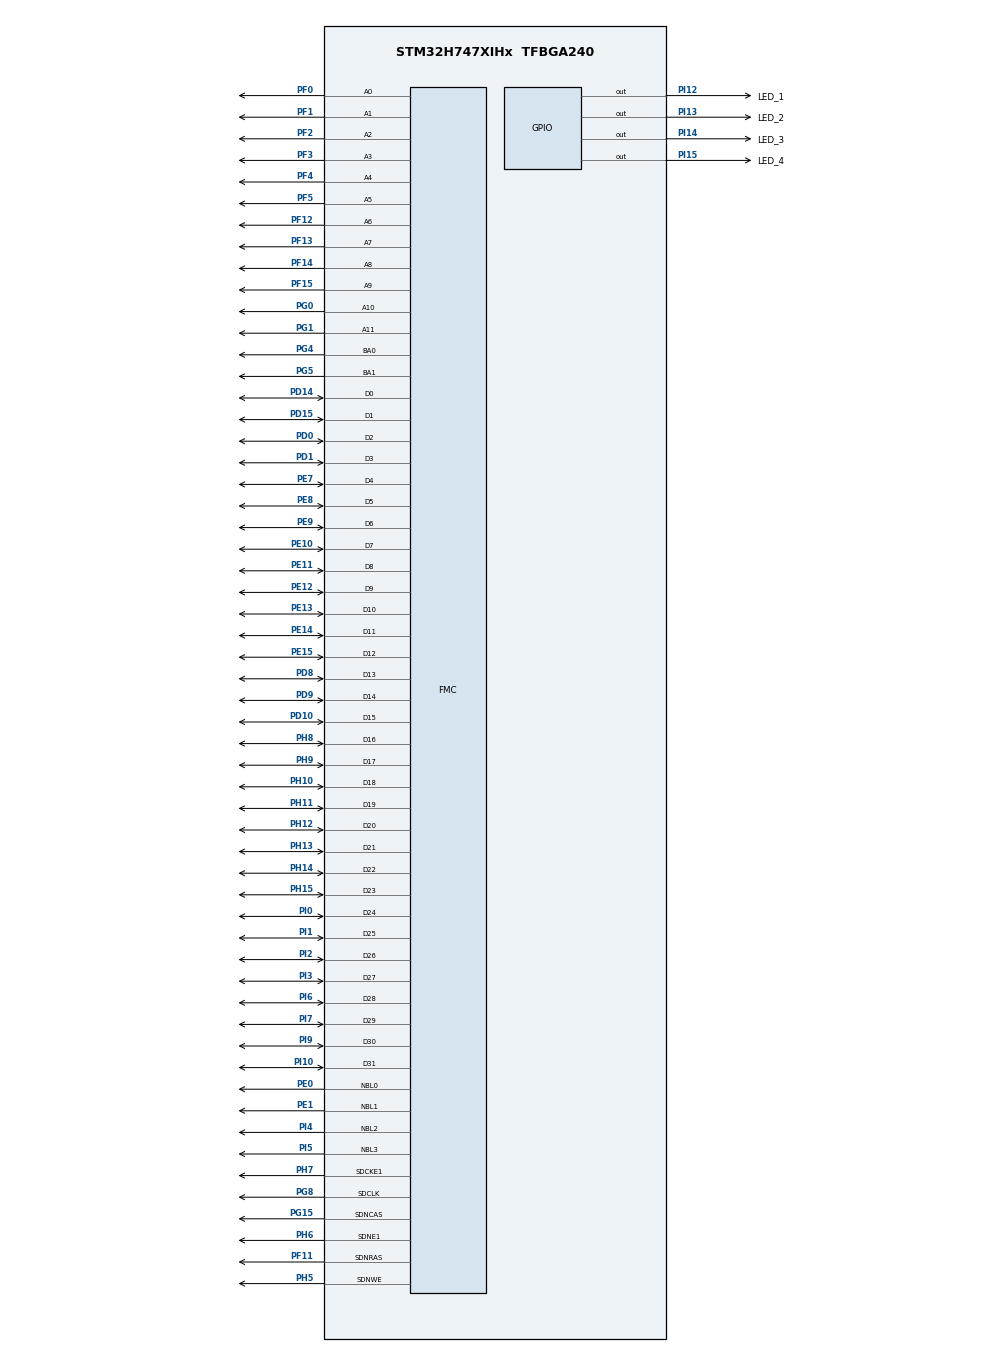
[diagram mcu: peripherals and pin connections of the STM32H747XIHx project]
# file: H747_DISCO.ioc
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CORTEX_M7.CPU_DCache=Enabled
CORTEX_M7.CPU_ICache=Enabled
CortexM4.IPs=BDMA,DMA,FATFS_M4\:I,FREERTOS_M4\:I,IWDG2\:I,MDMA,NVIC2\:I,RCC,USB_DEVICE_M4\:I,USB_HOST_M4\:I,WWDG2\:I,DEBUG,PDM2PCM_M4\:I,PWR,RESMGR_UTILITY,SYS_M4\:I,CORTEX_M4\:I,OPENAMP_M4\:I,VREFBUF,GPIO
CortexM4.Pins=PI14,PI15
CortexM7.IPs=BDMA\:I,DMA\:I,FATFS_M7\:I,FREERTOS_M7\:I,IWDG1\:I,MDMA\:I,NVIC1\:I,RCC\:I,USB_DEVICE_M7\:I,USB_HOST_M7\:I,WWDG1\:I,CORTEX_M7\:I,DEBUG\:I,PDM2PCM_M7\:I,PWR\:I,RESMGR_UTILITY\:I,SYS\:I,OPENAMP_M7\:I,VREFBUF\:I,GPIO\:I,FMC\:I
CortexM7.Pins=PI12,PI13
FMC.ColumnBitsNumber1=FMC_SDRAM_COLUMN_BITS_NUM_9
FMC.ReadPipeDelay1=FMC_SDRAM_RPIPE_DELAY_2
FMC.SDClockPeriod1=FMC_SDRAM_CLOCK_PERIOD_2
Mcu.Family=STM32H7
Mcu.Name=STM32H747XIHx
Mcu.Package=TFBGA240
NVIC1.PriorityGroup=NVIC_PRIORITYGROUP_4
NVIC2.PriorityGroup=NVIC_PRIORITYGROUP_4
PD0.PinAttribute=CortexM7
PD0.Signal=FMC_D2_DA2
PD1.PinAttribute=CortexM7
PD1.Signal=FMC_D3_DA3
PD10.PinAttribute=CortexM7
PD10.Signal=FMC_D15_DA15
PD14.PinAttribute=CortexM7
PD14.Signal=FMC_D0_DA0
PD15.PinAttribute=CortexM7
PD15.Signal=FMC_D1_DA1
PD8.PinAttribute=CortexM7
PD8.Signal=FMC_D13_DA13
PD9.PinAttribute=CortexM7
PD9.Signal=FMC_D14_DA14
PE0.PinAttribute=CortexM7
PE0.Signal=FMC_NBL0
PE1.PinAttribute=CortexM7
PE1.Signal=FMC_NBL1
PE10.PinAttribute=CortexM7
PE10.Signal=FMC_D7_DA7
PE11.PinAttribute=CortexM7
PE11.Signal=FMC_D8_DA8
PE12.PinAttribute=CortexM7
PE12.Signal=FMC_D9_DA9
PE13.PinAttribute=CortexM7
PE13.Signal=FMC_D10_DA10
PE14.PinAttribute=CortexM7
PE14.Signal=FMC_D11_DA11
PE15.PinAttribute=CortexM7
PE15.Signal=FMC_D12_DA12
PE7.PinAttribute=CortexM7
PE7.Signal=FMC_D4_DA4
PE8.PinAttribute=CortexM7
PE8.Signal=FMC_D5_DA5
PE9.PinAttribute=CortexM7
PE9.Signal=FMC_D6_DA6
PF0.PinAttribute=CortexM7
PF0.Signal=FMC_A0
PF1.PinAttribute=CortexM7
PF1.Signal=FMC_A1
PF11.PinAttribute=CortexM7
PF11.Signal=FMC_SDNRAS
PF12.PinAttribute=CortexM7
PF12.Signal=FMC_A6
PF13.PinAttribute=CortexM7
PF13.Signal=FMC_A7
PF14.PinAttribute=CortexM7
PF14.Signal=FMC_A8
PF15.PinAttribute=CortexM7
PF15.Signal=FMC_A9
PF2.PinAttribute=CortexM7
PF2.Signal=FMC_A2
PF3.PinAttribute=CortexM7
PF3.Signal=FMC_A3
PF4.PinAttribute=CortexM7
PF4.Signal=FMC_A4
PF5.PinAttribute=CortexM7
PF5.Signal=FMC_A5
PG0.PinAttribute=CortexM7
PG0.Signal=FMC_A10
PG1.PinAttribute=CortexM7
PG1.Signal=FMC_A11
PG15.PinAttribute=CortexM7
PG15.Signal=FMC_SDNCAS
PG4.PinAttribute=CortexM7
PG4.Signal=FMC_A14_BA0
PG5.PinAttribute=CortexM7
PG5.Signal=FMC_A15_BA1
PG8.PinAttribute=CortexM7
PG8.Signal=FMC_SDCLK
PH10.PinAttribute=CortexM7
PH10.Signal=FMC_D18
PH11.PinAttribute=CortexM7
PH11.Signal=FMC_D19
PH12.PinAttribute=CortexM7
PH12.Signal=FMC_D20
PH13.PinAttribute=CortexM7
PH13.Signal=FMC_D21
PH14.PinAttribute=CortexM7
PH14.Signal=FMC_D22
PH15.PinAttribute=CortexM7
PH15.Signal=FMC_D23
PH5.PinAttribute=CortexM7
PH5.Signal=FMC_SDNWE
PH6.Mode=SdramChipSelect2_1
PH6.PinAttribute=CortexM7
PH6.Signal=FMC_SDNE1
PH7.Mode=SdramChipSelect2_1
PH7.PinAttribute=CortexM7
PH7.Signal=FMC_SDCKE1
PH8.PinAttribute=CortexM7
PH8.Signal=FMC_D16
PH9.PinAttribute=CortexM7
PH9.Signal=FMC_D17
PI0.PinAttribute=CortexM7
PI0.Signal=FMC_D24
PI1.PinAttribute=CortexM7
PI1.Signal=FMC_D25
PI10.PinAttribute=CortexM7
PI10.Signal=FMC_D31
PI12.GPIO_Label=LED_1
PI12.PinAttribute=CortexM7
PI12.Signal=GPIO_Output
PI13.GPIO_Label=LED_2
PI13.PinAttribute=CortexM7
PI13.Signal=GPIO_Output
PI14.GPIO_Label=LED_3
PI14.PinAttribute=CortexM4
PI14.Signal=GPIO_Output
PI15.GPIO_Label=LED_4
PI15.PinAttribute=CortexM4
PI15.Signal=GPIO_Output
PI2.PinAttribute=CortexM7
PI2.Signal=FMC_D26
PI3.PinAttribute=CortexM7
PI3.Signal=FMC_D27
PI4.PinAttribute=CortexM7
PI4.Signal=FMC_NBL2
PI5.PinAttribute=CortexM7
PI5.Signal=FMC_NBL3
PI6.PinAttribute=CortexM7
PI6.Signal=FMC_D28
PI7.PinAttribute=CortexM7
PI7.Signal=FMC_D29
PI9.PinAttribute=CortexM7
PI9.Signal=FMC_D30
ProjectManager.HeapSize=M4-0x200,M7-0x200
ProjectManager.StackSize=M4-0x400,M7-0x400
ProjectManager.TargetToolchain=STM32CubeIDE
RCC.ADCFreq_Value=192000000
RCC.APB1Freq_Value=100000000
RCC.APB2Freq_Value=100000000
RCC.APB3Freq_Value=100000000
RCC.APB4Freq_Value=100000000
RCC.CortexFreq_Value=400000000
RCC.D1PPRE=RCC_APB3_DIV2
RCC.D2PPRE1=RCC_APB1_DIV2
RCC.D2PPRE2=RCC_APB2_DIV2
RCC.D3PPRE=RCC_APB4_DIV2
RCC.DIVM1=4
RCC.DIVM2=2
RCC.DIVN1=50
RCC.DIVN2=12
RCC.DIVQ1=5
RCC.HCLKFreq_Value=200000000
RCC.HPRE=RCC_HCLK_DIV2
RCC.PLL2FRACN=0
RCC.PLL3FRACN=0
RCC.PLLFRACN=0
RCC.PWR_Regulator_Voltage_Scale=PWR_REGULATOR_VOLTAGE_SCALE1
RCC.SYSCLKFreq_VALUE=400000000
RCC.SYSCLKSource=RCC_SYSCLKSOURCE_PLLCLK
RCC.SupplySource=PWR_DIRECT_SMPS_SUPPLY
RCC.USBFreq_Value=160000000
SH.FMC_A0.0=FMC_A0,12b-sda1
SH.FMC_A1.0=FMC_A1,12b-sda1
SH.FMC_A10.0=FMC_A10,12b-sda1
SH.FMC_A11.0=FMC_A11,12b-sda1
SH.FMC_A14_BA0.0=FMC_BA0,FourSdramBanks1
SH.FMC_A15_BA1.0=FMC_BA1,FourSdramBanks1
SH.FMC_A2.0=FMC_A2,12b-sda1
SH.FMC_A3.0=FMC_A3,12b-sda1
SH.FMC_A4.0=FMC_A4,12b-sda1
SH.FMC_A5.0=FMC_A5,12b-sda1
SH.FMC_A6.0=FMC_A6,12b-sda1
SH.FMC_A7.0=FMC_A7,12b-sda1
SH.FMC_A8.0=FMC_A8,12b-sda1
SH.FMC_A9.0=FMC_A9,12b-sda1
SH.FMC_D0_DA0.0=FMC_D0,sd-32b-d1
SH.FMC_D10_DA10.0=FMC_D10,sd-32b-d1
SH.FMC_D11_DA11.0=FMC_D11,sd-32b-d1
SH.FMC_D12_DA12.0=FMC_D12,sd-32b-d1
SH.FMC_D13_DA13.0=FMC_D13,sd-32b-d1
SH.FMC_D14_DA14.0=FMC_D14,sd-32b-d1
SH.FMC_D15_DA15.0=FMC_D15,sd-32b-d1
SH.FMC_D16.0=FMC_D16,sd-32b-d1
SH.FMC_D17.0=FMC_D17,sd-32b-d1
SH.FMC_D18.0=FMC_D18,sd-32b-d1
SH.FMC_D19.0=FMC_D19,sd-32b-d1
SH.FMC_D1_DA1.0=FMC_D1,sd-32b-d1
SH.FMC_D20.0=FMC_D20,sd-32b-d1
SH.FMC_D21.0=FMC_D21,sd-32b-d1
SH.FMC_D22.0=FMC_D22,sd-32b-d1
SH.FMC_D23.0=FMC_D23,sd-32b-d1
SH.FMC_D24.0=FMC_D24,sd-32b-d1
SH.FMC_D25.0=FMC_D25,sd-32b-d1
SH.FMC_D26.0=FMC_D26,sd-32b-d1
SH.FMC_D27.0=FMC_D27,sd-32b-d1
SH.FMC_D28.0=FMC_D28,sd-32b-d1
SH.FMC_D29.0=FMC_D29,sd-32b-d1
SH.FMC_D2_DA2.0=FMC_D2,sd-32b-d1
SH.FMC_D30.0=FMC_D30,sd-32b-d1
SH.FMC_D31.0=FMC_D31,sd-32b-d1
SH.FMC_D3_DA3.0=FMC_D3,sd-32b-d1
SH.FMC_D4_DA4.0=FMC_D4,sd-32b-d1
SH.FMC_D5_DA5.0=FMC_D5,sd-32b-d1
SH.FMC_D6_DA6.0=FMC_D6,sd-32b-d1
SH.FMC_D7_DA7.0=FMC_D7,sd-32b-d1
SH.FMC_D8_DA8.0=FMC_D8,sd-32b-d1
SH.FMC_D9_DA9.0=FMC_D9,sd-32b-d1
SH.FMC_NBL0.0=FMC_NBL0,Sd4ByteEnable1
SH.FMC_NBL1.0=FMC_NBL1,Sd4ByteEnable1
SH.FMC_NBL2.0=FMC_NBL2,Sd4ByteEnable1
SH.FMC_NBL3.0=FMC_NBL3,Sd4ByteEnable1
SH.FMC_SDCLK.0=FMC_SDCLK,12b-sda1
SH.FMC_SDNCAS.0=FMC_SDNCAS,12b-sda1
SH.FMC_SDNRAS.0=FMC_SDNRAS,12b-sda1
SH.FMC_SDNWE.0=FMC_SDNWE,12b-sda1
VP_SYS_M4_VS_Systick.Mode=SysTick
board=STM32H747I-DISCO

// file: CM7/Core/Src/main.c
/* USER CODE BEGIN Header */
/**
 ******************************************************************************
 * @file           : main.c
 * @brief          : Main program body
 ******************************************************************************
 * @attention
 *
 * Copyright (c) 2023 STMicroelectronics.
 * All rights reserved.
 *
 * This software is licensed under terms that can be found in the LICENSE file
 * in the root directory of this software component.
 * If no LICENSE file comes with this software, it is provided AS-IS.
 *
 ******************************************************************************
 */
/* USER CODE END Header */
#include "main.h"
#include "gpio.h"
#include "fmc.h"

/* USER CODE BEGIN Includes */
#include <string.h>
/* USER CODE END Includes */

/* USER CODE BEGIN PD */

#ifndef HSEM_ID_0
#define HSEM_ID_0 (0U) /* HW semaphore 0*/
#endif

/* USER CODE END PD */

void SystemClock_Config(void);

/* USER CODE BEGIN 0 */
uint32_t test_count = 0;
#define SDRAM_BASE_ADDRESS 0xD0000000

uint32_t sdram_base_address = SDRAM_BASE_ADDRESS;

uint32_t r_buf[1024] = {0x00, };
/* USER CODE END 0 */

int main(void)
{
    /* USER CODE BEGIN Boot_Mode_Sequence_0 */
//    int32_t timeout;
    /* USER CODE END Boot_Mode_Sequence_0 */

    /* Enable I-Cache---------------------------------------------------------*/
    SCB_EnableICache();

    /* Enable D-Cache---------------------------------------------------------*/
    SCB_EnableDCache();

    /* USER CODE BEGIN Boot_Mode_Sequence_1 */
    /* Wait until CPU2 boots and enters in stop mode or timeout*/
//    timeout = 0xFFFF;
//    while ((__HAL_RCC_GET_FLAG(RCC_FLAG_D2CKRDY) != RESET) && (timeout-- > 0));
//    if (timeout < 0)
//    {
//        Error_Handler();
//    }
    /* USER CODE END Boot_Mode_Sequence_1 */
    /* MCU Configuration--------------------------------------------------------*/

    /* Reset of all peripherals, Initializes the Flash interface and the Systick. */
    HAL_Init();

    /* Configure the system clock */
    SystemClock_Config();
    /* USER CODE BEGIN Boot_Mode_Sequence_2 */
    /* When system initialization is finished, Cortex-M7 will release Cortex-M4 by means of HSEM notification */
    /*HW semaphore Clock enable*/
//    __HAL_RCC_HSEM_CLK_ENABLE();
//    /*Take HSEM */
//    HAL_HSEM_FastTake(HSEM_ID_0);
//    /*Release HSEM in order to notify the CPU2(CM4)*/
//    HAL_HSEM_Release(HSEM_ID_0, 0);
//    /* wait until CPU2 wakes up from stop mode */
//    timeout = 0xFFFF;
//    while ((__HAL_RCC_GET_FLAG(RCC_FLAG_D2CKRDY) == RESET) && (timeout-- > 0));
//    if (timeout < 0)
//    {
//        Error_Handler();
//    }
    /* USER CODE END Boot_Mode_Sequence_2 */

    /* Initialize all configured peripherals */
    MX_GPIO_Init();
    MX_FMC_Init();
    /* USER CODE BEGIN 2 */

    // write
    uint32_t* p = (uint32_t*)SDRAM_BASE_ADDRESS;

    for (uint32_t i = 0; i < (0x02000000 / 4); i++)
    {
        *(p + i) = 0x12345678;
    }

    // read
    for (uint32_t i = 0; i < 1024; i++)
    {
        r_buf[i] = *(p + i);
    }
    /* USER CODE END 2 */

    /* Infinite loop */
    while (1)
    {

    }
}

void SystemClock_Config(void)
{
    RCC_OscInitTypeDef RCC_OscInitStruct = {0};
    RCC_ClkInitTypeDef RCC_ClkInitStruct = {0};

    /** Supply configuration update enable
     */
    HAL_PWREx_ConfigSupply(PWR_DIRECT_SMPS_SUPPLY);

    /** Configure the main internal regulator output voltage
     */
    __HAL_PWR_VOLTAGESCALING_CONFIG(PWR_REGULATOR_VOLTAGE_SCALE1);

    while (!__HAL_PWR_GET_FLAG(PWR_FLAG_VOSRDY))
    {
    }

    /** Initializes the RCC Oscillators according to the specified parameters
     * in the RCC_OscInitTypeDef structure.
     */
    RCC_OscInitStruct.OscillatorType = RCC_OSCILLATORTYPE_HSI;
    RCC_OscInitStruct.HSIState = RCC_HSI_DIV1;
    RCC_OscInitStruct.HSICalibrationValue = RCC_HSICALIBRATION_DEFAULT;
    RCC_OscInitStruct.PLL.PLLState = RCC_PLL_ON;
    RCC_OscInitStruct.PLL.PLLSource = RCC_PLLSOURCE_HSI;
    RCC_OscInitStruct.PLL.PLLM = 4;
    RCC_OscInitStruct.PLL.PLLN = 50;
    RCC_OscInitStruct.PLL.PLLP = 2;
    RCC_OscInitStruct.PLL.PLLQ = 5;
    RCC_OscInitStruct.PLL.PLLR = 2;
    RCC_OscInitStruct.PLL.PLLRGE = RCC_PLL1VCIRANGE_3;
    RCC_OscInitStruct.PLL.PLLVCOSEL = RCC_PLL1VCOWIDE;
    RCC_OscInitStruct.PLL.PLLFRACN = 0;
    if (HAL_RCC_OscConfig(&RCC_OscInitStruct) != HAL_OK)
    {
        Error_Handler();
    }

    /** Initializes the CPU, AHB and APB buses clocks
     */
    RCC_ClkInitStruct.ClockType = RCC_CLOCKTYPE_HCLK | RCC_CLOCKTYPE_SYSCLK
            | RCC_CLOCKTYPE_PCLK1 | RCC_CLOCKTYPE_PCLK2
            | RCC_CLOCKTYPE_D3PCLK1 | RCC_CLOCKTYPE_D1PCLK1;
    RCC_ClkInitStruct.SYSCLKSource = RCC_SYSCLKSOURCE_PLLCLK;
    RCC_ClkInitStruct.SYSCLKDivider = RCC_SYSCLK_DIV1;
    RCC_ClkInitStruct.AHBCLKDivider = RCC_HCLK_DIV2;
    RCC_ClkInitStruct.APB3CLKDivider = RCC_APB3_DIV2;
    RCC_ClkInitStruct.APB1CLKDivider = RCC_APB1_DIV2;
    RCC_ClkInitStruct.APB2CLKDivider = RCC_APB2_DIV2;
    RCC_ClkInitStruct.APB4CLKDivider = RCC_APB4_DIV2;

    if (HAL_RCC_ClockConfig(&RCC_ClkInitStruct, FLASH_LATENCY_2) != HAL_OK)
    {
        Error_Handler();
    }
}

void Error_Handler(void)
{
    __disable_irq();
    while (1)
    {
    }
}
